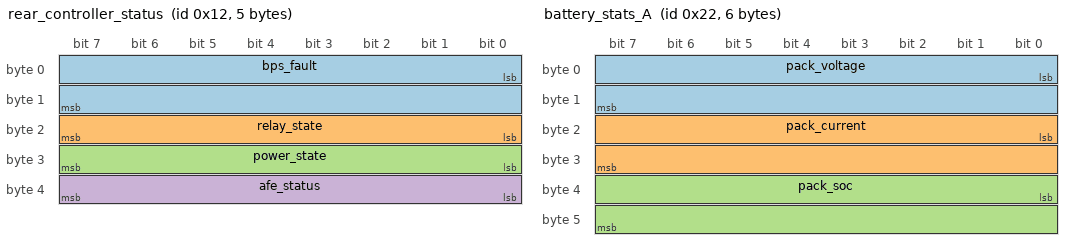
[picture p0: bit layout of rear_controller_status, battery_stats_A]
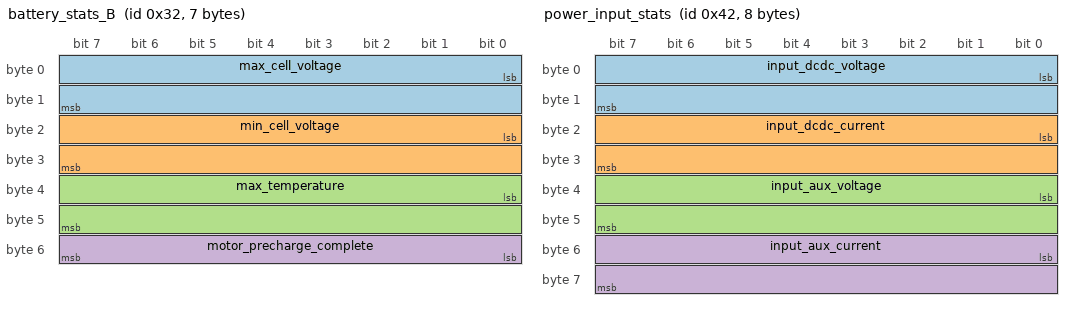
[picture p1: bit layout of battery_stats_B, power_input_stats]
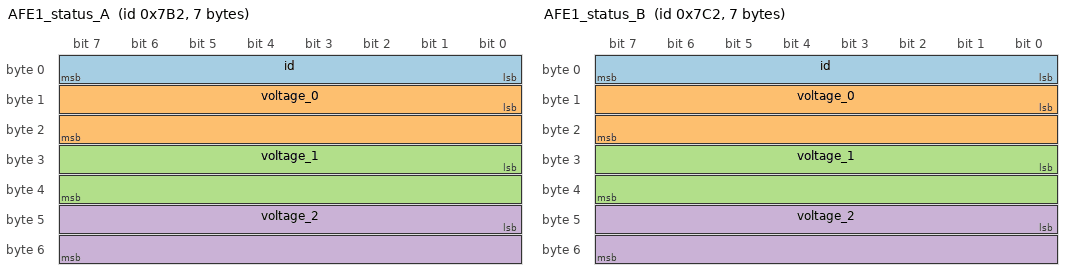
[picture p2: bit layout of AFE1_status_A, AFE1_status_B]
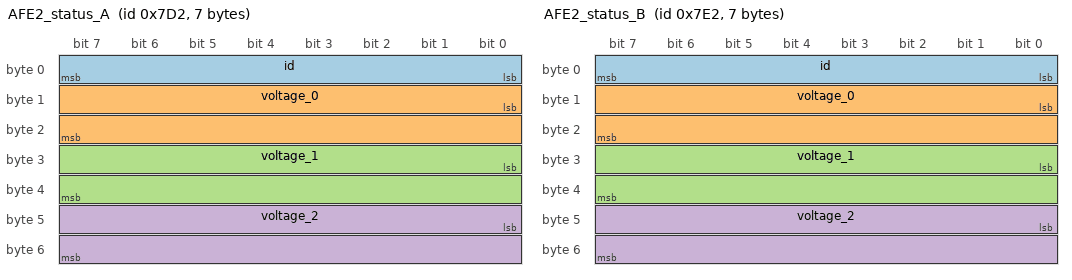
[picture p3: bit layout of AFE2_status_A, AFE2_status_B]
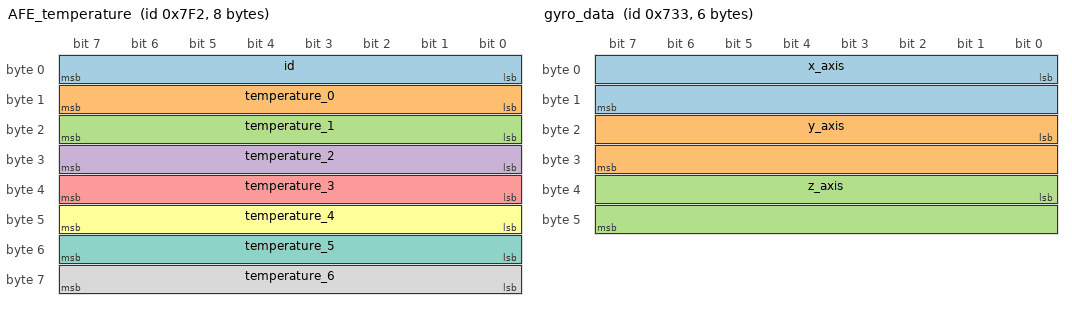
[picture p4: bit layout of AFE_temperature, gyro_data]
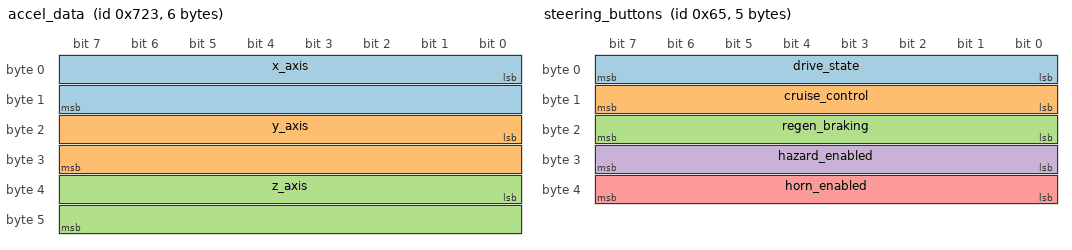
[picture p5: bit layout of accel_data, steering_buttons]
NS_ :

BS_:

BU_: TELEMETRY FRONT_CONTROLLER REAR_CONTROLLER IMU CAN_COMMUNICATION STEERING

BO_   1856 telemetry: 8 telemetry
  SG_ telemetry_data : 0|64@1+ (1,0) [0|18446744073709551615] "" telemetry

BO_   1361 front_controller_pedal_data: 5 front_controller
  SG_ percentage : 0|32@1+ (1,0) [0|4294967295] "" telemetry, rear_controller
  SG_ brake_enabled : 32|8@1+ (1,0) [0|255] "" telemetry, rear_controller

BO_  18  rear_controller_status: 5 rear_controller
  SG_ bps_fault : 0|16@1+ (1,0) [0|65535] "" telemetry, front_controller, steering
  SG_ relay_state : 16|8@1+ (1,0) [0|255] "" telemetry, front_controller, steering
  SG_ power_state : 24|8@1+ (1,0) [0|255] "" telemetry, front_controller, steering
  SG_ afe_status : 32|8@1+ (1,0) [0|255] "" telemetry, front_controller, steering

BO_  34  battery_stats_A: 6 rear_controller
  SG_ pack_voltage : 0|16@1+ (1,0) [0|65535] "" telemetry, front_controller, steering
  SG_ pack_current : 16|16@1+ (1,0) [0|65535] "" telemetry, front_controller, steering
  SG_ pack_soc : 32|16@1+ (1,0) [0|65535] "" telemetry, front_controller, steering

BO_  50  battery_stats_B: 7 rear_controller
  SG_ max_cell_voltage : 0|16@1+ (1,0) [0|65535] "" telemetry, front_controller, steering
  SG_ min_cell_voltage : 16|16@1+ (1,0) [0|65535] "" telemetry, front_controller, steering
  SG_ max_temperature : 32|16@1+ (1,0) [0|65535] "" telemetry, front_controller, steering
  SG_ motor_precharge_complete : 48|8@1+ (1,0) [0|255] "" telemetry, front_controller, steering

BO_  66  power_input_stats: 8 rear_controller
  SG_ input_dcdc_voltage : 0|16@1+ (1,0) [0|65535] "" telemetry, steering
  SG_ input_dcdc_current : 16|16@1+ (1,0) [0|65535] "" telemetry, steering
  SG_ input_aux_voltage : 32|16@1+ (1,0) [0|65535] "" telemetry, steering
  SG_ input_aux_current : 48|16@1+ (1,0) [0|65535] "" telemetry, steering

BO_   1970 AFE1_status_A: 7 rear_controller
  SG_ id : 0|8@1+ (1,0) [0|255] "" telemetry, steering
  SG_ voltage_0 : 8|16@1+ (1,0) [0|65535] "" telemetry, steering
  SG_ voltage_1 : 24|16@1+ (1,0) [0|65535] "" telemetry, steering
  SG_ voltage_2 : 40|16@1+ (1,0) [0|65535] "" telemetry, steering

BO_   1986 AFE1_status_B: 7 rear_controller
  SG_ id : 0|8@1+ (1,0) [0|255] "" telemetry, steering
  SG_ voltage_0 : 8|16@1+ (1,0) [0|65535] "" telemetry, steering
  SG_ voltage_1 : 24|16@1+ (1,0) [0|65535] "" telemetry, steering
  SG_ voltage_2 : 40|16@1+ (1,0) [0|65535] "" telemetry, steering

BO_   2002 AFE2_status_A: 7 rear_controller
  SG_ id : 0|8@1+ (1,0) [0|255] "" telemetry, steering
  SG_ voltage_0 : 8|16@1+ (1,0) [0|65535] "" telemetry, steering
  SG_ voltage_1 : 24|16@1+ (1,0) [0|65535] "" telemetry, steering
  SG_ voltage_2 : 40|16@1+ (1,0) [0|65535] "" telemetry, steering

BO_   2018 AFE2_status_B: 7 rear_controller
  SG_ id : 0|8@1+ (1,0) [0|255] "" telemetry, steering
  SG_ voltage_0 : 8|16@1+ (1,0) [0|65535] "" telemetry, steering
  SG_ voltage_1 : 24|16@1+ (1,0) [0|65535] "" telemetry, steering
  SG_ voltage_2 : 40|16@1+ (1,0) [0|65535] "" telemetry, steering

BO_   2034 AFE_temperature: 8 rear_controller
  SG_ id : 0|8@1+ (1,0) [0|255] "" telemetry, steering
  SG_ temperature_0 : 8|8@1+ (1,0) [0|255] "" telemetry, steering
  SG_ temperature_1 : 16|8@1+ (1,0) [0|255] "" telemetry, steering
  SG_ temperature_2 : 24|8@1+ (1,0) [0|255] "" telemetry, steering
  SG_ temperature_3 : 32|8@1+ (1,0) [0|255] "" telemetry, steering
  SG_ temperature_4 : 40|8@1+ (1,0) [0|255] "" telemetry, steering
  SG_ temperature_5 : 48|8@1+ (1,0) [0|255] "" telemetry, steering
  SG_ temperature_6 : 56|8@1+ (1,0) [0|255] "" telemetry, steering

BO_   1843 gyro_data: 6 imu
  SG_ x_axis : 0|16@1+ (1,0) [0|65535] "" telemetry
  SG_ y_axis : 16|16@1+ (1,0) [0|65535] "" telemetry
  SG_ z_axis : 32|16@1+ (1,0) [0|65535] "" telemetry

BO_   1827 accel_data: 6 imu
  SG_ x_axis : 0|16@1+ (1,0) [0|65535] "" telemetry
  SG_ y_axis : 16|16@1+ (1,0) [0|65535] "" telemetry
  SG_ z_axis : 32|16@1+ (1,0) [0|65535] "" telemetry

BO_   1908 fast_one_shot_msg: 4 can_communication
  SG_ sig1 : 0|16@1+ (1,0) [0|65535] "" can_communication
  SG_ sig2 : 16|16@1+ (1,0) [0|65535] "" can_communication

BO_   1892 medium_one_shot_msg: 4 can_communication
  SG_ sig1 : 0|16@1+ (1,0) [0|65535] "" can_communication
  SG_ sig2 : 16|16@1+ (1,0) [0|65535] "" can_communication

BO_   1876 slow_one_shot_msg: 4 can_communication
  SG_ sig1 : 0|16@1+ (1,0) [0|65535] "" can_communication
  SG_ sig2 : 16|16@1+ (1,0) [0|65535] "" can_communication

BO_  101  steering_buttons: 5 steering
  SG_ drive_state : 0|8@1+ (1,0) [0|255] "" telemetry, rear_controller
  SG_ cruise_control : 8|8@1+ (1,0) [0|255] "" telemetry, rear_controller
  SG_ regen_braking : 16|8@1+ (1,0) [0|255] "" telemetry, rear_controller
  SG_ hazard_enabled : 24|8@1+ (1,0) [0|255] "" telemetry, rear_controller
  SG_ horn_enabled : 32|8@1+ (1,0) [0|255] "" telemetry, rear_controller

BO_  85  steering_target_velocity: 4 steering
  SG_ target_velocity : 0|32@1+ (1,0) [0|4294967295] "" telemetry, rear_controller
